# CUSTEFUSE_PRM register map
Vendor: Texas Instruments
Peripheral module from a debugger description file (folder TDA2Ex).
Registers are 32-bit, access per field, reset 0x0 unless marked. A register's access mark holds for its fields unless they carry their own. Offsets are as the file gives them; lines under a group give offsets from that group; [hi:lo] are bit positions; {n}, {i} and the like mark numbered series; 'fields as' and 'values as' point back to an identical list; <NAME> marks a mode.

## CUSTEFUSE_PRM
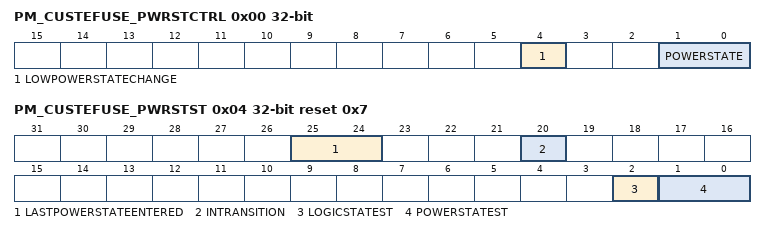
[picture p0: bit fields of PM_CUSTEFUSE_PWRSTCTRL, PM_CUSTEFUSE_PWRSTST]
0x00 PM_CUSTEFUSE_PWRSTCTRL — This register controls the CUSTEFUSE power state to reach upon a domain sleep transition
  [4] LOWPOWERSTATECHANGE rw — Power state change request when domain has already performed a sleep transition. Allows going into deeper low power state without waking up the power domain.
    0=DIS (Do not request a low power state change.); 1=EN (Request a low power state change. This bit is automatically cleared when the power state is effectively changed or when power state is ON.)
  [1:0] POWERSTATE rw — Power state controlNote: This bit field is not functional for SR2.x devices.
    0=OFF (OFF state); 2=INACT (INACTIVE state); 3=ON (ON State)
0x04 PM_CUSTEFUSE_PWRSTST reset 0x7 — This register provides a status on the current CUSTEFUSE power domain state. [warm reset insensitive]
  [25:24] LASTPOWERSTATEENTERED rw — Last low power state entered. Set to 0x3 upon write of the same only. This register is intended for debug purpose only.
    0=OFF (Power domain was previously OFF); 1=RET (Power domain was previously in RETENTION); 2=INACTIVE (Power domain was previously ON-INACTIVE); 3=ON (Power domain was previously ON-ACTIVE)
  [20] INTRANSITION ro — Domain transition status
    0=NO (No on-going transition on power domain); 1=ONGOING (Power domain transition is in progress.)
  [2] LOGICSTATEST ro — Logic state status
    0=OFF (Logic in domain is OFF); 1=ON (Logic in domain is ON)
  [1:0] POWERSTATEST ro — Current power state status
    0=OFF (Power domain is OFFNote: This bit field value is not valid for SR2.x devices.); 1=RET (Power domain is in RETENTION); 2=INACTIVE (Power domain is ON-INACTIVE); 3=ON (Power domain is ON-ACTIVE)
0x24 RM_CUSTEFUSE_EFUSE_CTRL_CUST_CONTEXT reset 0x1 — This register contains dedicated CUSTEFUSE module context statuses. [warm reset insensitive]
  [0] LOSTCONTEXT_DFF rw — Specify if DFF-based context has been lost due to a previous power transition or other reset source. (set upon assertion of CUSTEFUSE_RST signal)
    0=MAINTAINED (Context has been maintained); 1=LOST (Context has been lost)
